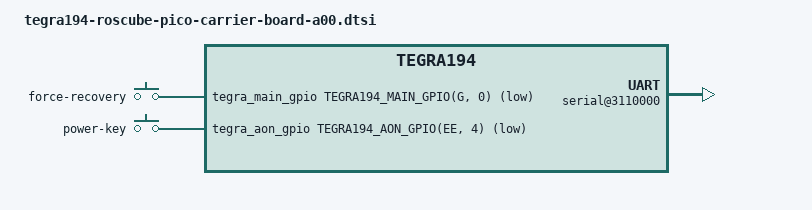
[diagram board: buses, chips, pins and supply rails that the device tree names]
/*
 * Copyright (c) 2019, NVIDIA CORPORATION.  All rights reserved.
 *
 * This program is free software; you can redistribute it and/or modify
 * it under the terms of the GNU General Public License as published by
 * the Free Software Foundation; version 2 of the License.
 *
 * This program is distributed in the hope that it will be useful, but WITHOUT
 * ANY WARRANTY; without even the implied warranty of MERCHANTABILITY or
 * FITNESS FOR A PARTICULAR PURPOSE.  See the GNU General Public License for
 * more details.
 */
#include <dt-bindings/gpio/tegra194-gpio.h>
#include "dt-bindings/input/input.h"
#include "tegra194-fixed-regulator-p3509-0000-a00.dtsi"
#include "tegra194-p3509-disp.dtsi"
#include "tegra194-audio-p3668.dtsi"
#include "tegra194-roscube-extern-header.dtsi"
#include "tegra194-roscube-fan.dtsi"

/ {
	gpio-keys {
		compatible = "gpio-keys";
		gpio-keys,name = "gpio-keys";

		forcerecovery {
			label = "force-recovery";
			gpios = <&tegra_main_gpio TEGRA194_MAIN_GPIO(G, 0) GPIO_ACTIVE_LOW>;
			linux,code = <BTN_1>;
		};

		power_key {
			label = "power-key";
			gpios = <&tegra_aon_gpio TEGRA194_AON_GPIO(EE, 4) GPIO_ACTIVE_LOW>;
			linux,code = <KEY_POWER>;
			gpio-key,wakeup;
		};
	};
	
	eeprom-manager {
		data-size = <0x100>;
		bus@0 {
			i2c-bus = <&gen1_i2c>;
			eeprom@1 {
				slave-address = <0x57>;
				label = "cvb";
			};
		};
	};

	serial@3110000 { /* External Header provided UART */
		status = "okay";
	};

	gpio@2200000 {
		/* gpio-name for 40-pin header, gpio-name given as COL(10) x ROW(24),
		   Tegra-GPIO starts from 288 */
		gpio-line-names = "",   "",     "",     "",     "",     "",     "",     "",     "",     "",
		"",     "",     "",     "",     "",     "",     "",     "",     "",     "",
		"",     "",     "",     "",     "",     "",     "",     "",     "",     "",
		"",     "",     "",     "",     "",     "",     "",     "",     "",     "",
		"",     "",     "",     "",     "",     "",     "",     "",     "",     "",
		"",     "",     "",     "",     "",     "",     "",     "",     "",     "",
		"",     "",     "",     "",     "",     "",     "",     "",     "",     "",
		"",     "",     "",     "",     "",     "",     "",     "",     "",     "",
		"",     "",     "",     "",     "",     "",     "",     "",     "",     "",
		"",     "",     "",     "",     "",     "",     "",     "",     "",     "",
		"",     "",     "",     "",     "",     "GPIO13",     "",     "",     "",     "",
		"",     "",     "",     "",     "",     "",     "",     "",     "",     "",
		"",     "",     "",     "",     "",     "",     "",     "",     "",     "",
		"",     "",     "",     "GPIO01",     "GPIO11",     "",     "GPIO07",     "",     "",     "",
		"UART1_RTS",     "UART1_CTS",     "",     "",     "",     "",     "",     "",     "GPIO09",     "",
		"",     "",     "",     "",     "",     "",     "",     "I2S0_SCLK",     "I2S0_DOUT",     "I2S0_DIN",
		"I2S0_FS",     "",     "",     "",     "",     "",     "",     "",     "",     "",
		"",     "",     "",     "",     "",     "",     "",     "",     "",     "",
		"",     "",     "",     "",     "",     "",     "",     "",     "",     "",
		"",     "",     "SPI1_SCK",     "SPI1_MISO",     "SPI1_MOSI",     "SPI1_CS0",     "SPI1_CS1",     "",     "",     "",
		"",     "",     "",     "SPI0_SCK",     "SPI0_MISO",     "SPI0_MOSI",     "SPI0_CS0",     "SPI0_CS1",     "",     "",
		"",     "",     "",     "",     "",     "",     "",     "",     "",     "",
		"",     "",     "",     "",     "",     "",     "",     "",     "",     "",
		"",     "",     "",     "",     "",     "",     "",     "",     "",     "";
	};

	gpio@c2f0000 {
		/* gpio-name for 40-pin header, gpio-name given as COL(10) x ROW(2),
		   Tegra-AON-GPIO starts from 248 */
		gpio-line-names = "",   "",     "",     "",     "",     "",     "",     "",     "",     "",
		"",     "",     "",     "",     "",     "",     "",     "",     "",     "",     "GPIO12";
	};
};
